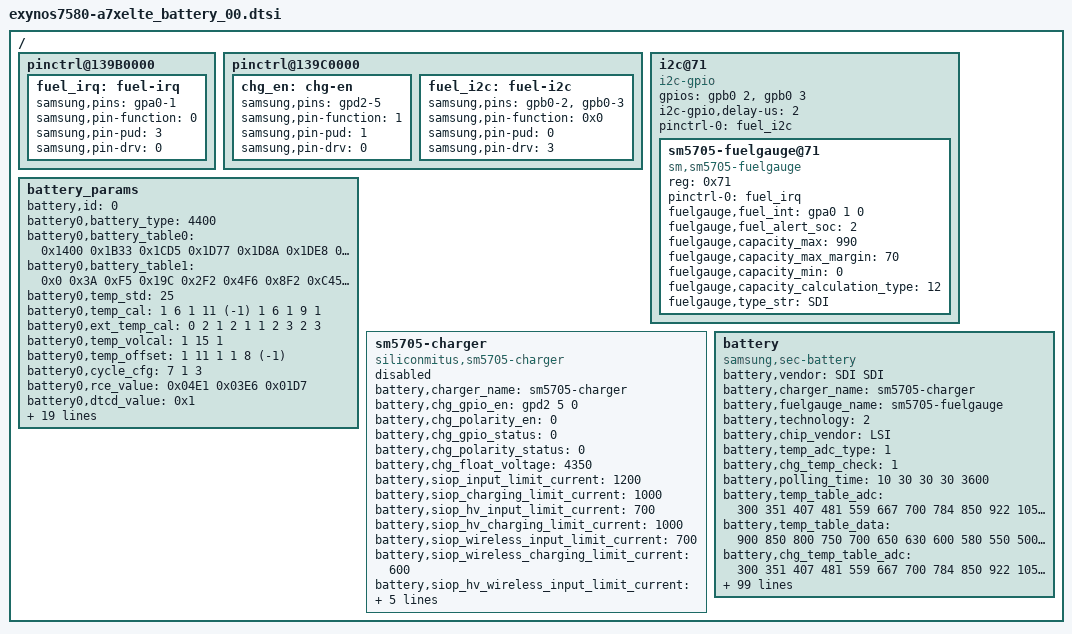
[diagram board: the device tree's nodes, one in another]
/*
 * SAMSUNG UNIVERSAL5430 board device tree source
 *
 * Copyright (c) 2013 Samsung Electronics Co., Ltd.
 *		http://www.samsung.com
 *
 * This program is free software; you can redistribute it and/or modify
 * it under the terms of the GNU General Public License version 2 as
 * published by the Free Software Foundation.
*/

/ {
	pinctrl@139B0000 {
		fuel_irq: fuel-irq {
			samsung,pins = "gpa0-1";
			samsung,pin-function = <0>;
			samsung,pin-pud = <3>;
			samsung,pin-drv = <0>;
		};
	};

	pinctrl@139C0000 {
		chg_en: chg-en {
			samsung,pins = "gpd2-5";
			samsung,pin-function = <1>;
			samsung,pin-pud = <1>;
			samsung,pin-drv = <0>;
		};

		fuel_i2c: fuel-i2c {
			samsung,pins = "gpb0-2", "gpb0-3";
			samsung,pin-function = <0x0>;
			samsung,pin-pud = <0>;
			samsung,pin-drv = <3>;
		};
	};

	i2c@71 {
		compatible = "i2c-gpio";
		gpios = <&gpb0 2 0x0 /*sda*/
			&gpb0 3 0x0  /*scl*/
			>;
		i2c-gpio,delay-us = <2>;
		#address-cells = <1>;
		#size-cells = <0>;
		pinctrl-names = "default";
		pinctrl-0 = <&fuel_i2c>;
		status = "okay";

		sm5705-fuelgauge@71 {
			compatible = "sm,sm5705-fuelgauge";
			reg = <0x71>;
			pinctrl-names = "default";
			pinctrl-0 = <&fuel_irq>;
			fuelgauge,fuel_int = <&gpa0 1 0>;
			fuelgauge,fuel_alert_soc = <2>;
			fuelgauge,capacity_max = <990>;
			fuelgauge,capacity_max_margin = <70>;
			fuelgauge,capacity_min = <0>;
			fuelgauge,capacity_calculation_type = <12>;
			fuelgauge,type_str = "SDI";
		};
	};

	battery_params {
		battery,id = <0>; /* -1 means auto, detected by F/G */
		battery0,battery_type = <4400>; /* 4200 4350 4400 */
		battery0,battery_table0 = <0x1400 0x1B33 0x1CD5 0x1D77 0x1D8A 0x1DE8 0x1E50 0x1EA7 0x1EFE 0x1F9D 0x1FF3 0x2090 0x20AA 0x2147 0x2266 0x2400>;
		battery0,battery_table1 = <0x0 0x3A 0xF5 0x19C 0x2F2 0x4F6 0x8F2 0xC45 0xE49 0x1047 0x1245 0x139B 0x1442 0x1646 0x1933 0x1939>;
		battery0,temp_std = <25>;
		battery0,temp_cal = <1 6 1 11 (-1) 1 6 1 9 1>; /* en_h, p_de, p_fa, n_de, n_fa, en_l, p_de, p_fa, n_de, n_fa, */
		battery0,ext_temp_cal = <0 2 1 2 1 1 2 3 2 3>; /* en_h, p_de, p_fa, n_de, n_fa, en_l, p_de, p_fa, n_de, n_fa, */
		battery0,temp_volcal = <1 15 1>; /* en, temp, cal */
		battery0,temp_offset = <1 11 1 1 8 (-1)>; /* en_high level offset en_low level offset */
		battery0,cycle_cfg = <7 1 3>; /*high_limit low_limit cntl*/
		battery0,rce_value = <0x04E1 0x03E6 0x01D7>;
		battery0,dtcd_value = <0x1>;
		battery0,rs_value = <0x0051 0x147 0x47a 0x3800 0x00a4>; /*rs p_mix_factor n_mix_factor max min*/
		battery0,vit_period = <0x3506>;
		battery0,mix_value = <0x0503 0x0004>; /*mix_rate init_blank*/
		battery0,misc = <0x0060>;
		battery0,topoff_soc = <0 3 300>; /*enable soc current*/
		battery0,curr_offset = <1 0x0000>; /*en_auto offset*/
		battery0,volt_cal = <0x8000>;
		battery0,p_curr_cal = <0x009C>;
		battery0,n_curr_cal = <0x009C>;
		battery0,curr_lcal = <0 0x8888 0x8888 0x8888>;
		battery0,tem_poff = <3350 50 3200 50>;
		battery0,v_offset_cancel = <1 0 100 10>; /* en_p, en_n, level, mohm */
		battery0,v_alarm = <3000>;
		battery0,v_max_table = <0x2266 0x223C 0x2212 0x21E8 0x217F>;
		battery0,q_max_table = <0x1933 0x18CB 0x1863 0x17FC 0x16F8>;
		battery0,data_ver = <0x8>; /* this is must set value same with .version in BL */
	};

	sm5705-charger {
		status = "disable";
		compatible = "siliconmitus,sm5705-charger";

		/* Charger */
		battery,charger_name = "sm5705-charger";
		battery,chg_gpio_en = <&gpd2 5 0>;
		battery,chg_polarity_en = <0>;
		battery,chg_gpio_status = <0>;
		battery,chg_polarity_status = <0>;
		battery,chg_float_voltage = <4350>;

		battery,siop_input_limit_current = <1200>;
		battery,siop_charging_limit_current = <1000>;
		battery,siop_hv_input_limit_current = <700>;
		battery,siop_hv_charging_limit_current = <1000>;

		battery,siop_wireless_input_limit_current = <700>;
		battery,siop_wireless_charging_limit_current = <600>;
		battery,siop_hv_wireless_input_limit_current = <500>;
		battery,siop_hv_wireless_charging_limit_current = <1000>;
		battery,siop_call_cv_current = <500>;
		battery,siop_call_cc_current = <500>;
	};

	battery {
		status = "okay";

		compatible = "samsung,sec-battery";
		battery,vendor = "SDI SDI";
		battery,charger_name = "sm5705-charger";
		battery,fuelgauge_name = "sm5705-fuelgauge";
		battery,technology = <2>; /* POWER_SUPPLY_TECHNOLOGY_LION */
		/* .temp_cohot = -1000; */
		/* .temp_cocold = -4325; */

		battery,chip_vendor = "LSI";
		battery,temp_adc_type = <1>; /* SEC_BATTERY_ADC_TYPE_AP */

		battery,chg_temp_check = <1>;

		battery,polling_time = <10 30 30 30 3600>;

		battery,temp_table_adc = <300 351 407 481 559 667 700 784 850 922 1056 1189 1404 1602 2026 2245 2460 2874 2932 3180 3229 3305 3335 3410>;
		battery,temp_table_data = <900 850 800 750 700 650 630 600 580 550 500 460 400 350 250 200 150 50 0 (-50) (-70) (-100) (-150) (-200)>;

		battery,chg_temp_table_adc = <300 351 407 481 559 667 700 784 850 922 1056 1189 1404 1602 2026 2245 2460 2874 2932 3180 3229 3305 3335 3410>;
		battery,chg_temp_table_data = <900 850 800 750 700 650 630 600 580 550 500 460 400 350 250 200 150 50 0 (-50) (-70) (-100) (-150) (-200)>;

		battery,input_current_limit = <1800 0 0 1800 460 900 1000 460 1000 0 820 1900 1800 0 0 400 700 1300 300 1000 1500 0 1650 500 1650 80 1800 1650 1400 1000 1000 1800>;
		battery,fast_charging_current = <2100 0 0 2100 460 1200 1000 460 1200 0 1200 1600 2100 0 0 400 700 1300 300 1000 1500 0 2350 1000 2350 80 1800 1000 1400 0 1000 2100>;
		battery,full_check_current_1st = <325 0 0 325 325 325 325 325 325 0 325 325 325 0 0 325 325 325 325 325 325 0 325 325 325 0 325 325 325 0 325 325>; /* 0.1C */
		battery,full_check_current_2nd = <175 0 0 175 175 175 175 175 175 0 175 175 175 0 0 175 175 175 175 175 175 0 175 175 175 0 175 175 175 0 175 175>; /*0.05C */

		battery,inbat_voltage = <1>;
		battery,inbat_voltage_table_adc = <2739 2722 2697 2678 2643 2628 2599 2573 2547 2521 2495 2474 2440 2423 2393 2359 2347 2317 2291 2267 2240>;
		battery,inbat_voltage_table_data = <438 435 430 426 419 416 410 405 400 395 390 385 380 375 370 365 360 355 350 345 340>;

		battery,adc_check_count = <5>;

		battery,cable_check_type = <4>; /* SEC_BATTERY_CABLE_CHECK_PSY */
		battery,cable_source_type = <1>; /* SEC_BATTERY_CABLE_SOURCE_EXTERNAL */
		battery,event_waiting_time = <600>;
		battery,polling_type = <1>; /* SEC_BATTERY_MONITOR_ALARM */
		battery,monitor_initial_count = <0>;

		battery,battery_check_type = <0>; /* SEC_BATTERY_CHECK_NONE */
		battery,check_count = <0>;
		battery,check_adc_max = <1440>;
		battery,check_adc_min = <0>;

		battery,ovp_uvlo_check_type = <3>; /* SEC_BATTERY_OVP_UVLO_CHGPOLLING */

		battery,thermal_source = <2>; /* SEC_BATTERY_THERMAL_SOURCE_ADC */

		battery,temp_check_type = <2>; /* SEC_BATTERY_TEMP_CHECK_TEMP */
		battery,temp_check_count = <1>;
		battery,temp_highlimit_threshold_event = <800>;
		battery,temp_highlimit_recovery_event = <750>;
		battery,temp_high_threshold_event = <500>;
		battery,temp_high_recovery_event = <450>;
		battery,temp_low_threshold_event = <0>;
		battery,temp_low_recovery_event = <50>;
		battery,temp_highlimit_threshold_normal = <800>;
		battery,temp_highlimit_recovery_normal = <750>;
		battery,temp_high_threshold_normal = <500>;
		battery,temp_high_recovery_normal = <450>;
		battery,temp_low_threshold_normal = <0>;
		battery,temp_low_recovery_normal = <50>;
		battery,temp_highlimit_threshold_lpm = <800>;
		battery,temp_highlimit_recovery_lpm = <750>;
		battery,temp_high_threshold_lpm = <500>;
		battery,temp_high_recovery_lpm = <450>;
		battery,temp_low_threshold_lpm = <0>;
		battery,temp_low_recovery_lpm = <50>;
		battery,full_check_type = <2>; /* SEC_BATTERY_FULLCHARGED_FG_CURRENT */
		battery,full_check_type_2nd = <2>; /* SEC_BATTERY_FULLCHARGED_FG_CURRENT */
		battery,full_check_count = <3>;
		battery,chg_gpio_full_check = <0>;
		battery,chg_polarity_full_check = <1>;

		battery,chg_high_temp_1st = <465>;
		battery,chg_high_temp_2nd = <465>;
		battery,chg_high_temp_recovery = <455>;
		battery,chg_charging_limit_current = <1400>;
		battery,chg_charging_limit_current_2nd = <1400>;
		battery,chg_skip_check_capacity = <10>;
		battery,chg_skip_check_time = <600>;

		/* SEC_BATTERY_FULL_CONDITION_SOC |
		   SEC_BATTERY_FULL_CONDITION_NOTIMEFULL |
		   SEC_BATTERY_FULL_CONDITION_VCELL */
		battery,full_condition_type = <13>;
		battery,full_condition_soc = <93>;
		battery,full_condition_vcell = <4250>;

		battery,recharge_check_count = <2>;
		battery,recharge_condition_type = <4>; /* SEC_BATTERY_RECHARGE_CONDITION_VCELL */
		battery,recharge_condition_soc = <98>;
		battery,recharge_condition_vcell = <4280>;

		battery,standard_curr = <2350>;
		battery,expired_time = <12000>;
		battery,recharging_expired_time = <5400>;
		battery,charging_reset_time = <0>;

		battery,chg_float_voltage = <4350>;

		/*battery,self_discharging_en;*/
		battery,self_discharging_type = <2>;	/* SELF_DISCHARGING_BY_CHG */
		battery,force_discharging_limit = <650>;
		battery,force_discharging_recov = <550>;
		battery,self_discharging_voltage_limit = <4250>;

		battery,self_discharging_temp_block = <600>;
		battery,self_discharging_volt_block = <4250>;
		battery,self_discharging_temp_recov = <550>;
		battery,self_discharging_temp_pollingtime = <400>;

		/* swelling setting */
		battery,swelling_low_temp_2step_mode = <1>;
		battery,swelling_high_temp_block = <410>;
		battery,swelling_high_temp_recov = <390>;
		battery,swelling_low_temp_block_1st = <150>;
		battery,swelling_low_temp_recov_1st = <200>;
		battery,swelling_low_temp_block_2nd = <50>;
		battery,swelling_low_temp_recov_2nd = <100>;

		battery,swelling_low_temp_current = <950>;		/* 0.3C */
		battery,swelling_low_temp_topoff = <175>;		/* 0.05C */
		battery,swelling_high_temp_current = <1450>;	/* 0.45C */
		battery,swelling_high_temp_topoff = <175>;		/* 0.05C */

		battery,swelling_drop_float_voltage = <4150>;
		battery,swelling_high_rechg_voltage = <4000>;
		battery,swelling_low_rechg_voltage = <4000>;
		battery,swelling_block_time = <600>;

		/* cycle, chg_float_voltage, recharge_condition_vcell, full_condition_vcell, full_condition_soc */
		battery,age_data = <0 4350 4280 4250 93
				200 4330 4260 4230 92
				250 4310 4240 4210 91
				300 4290 4220 4190 90
				1000 4240 4170 4140 89>;

		io-channels = <&exynos_adc 1>, <&exynos_adc 3>, <&exynos_adc 4>;
		io-channel-names = "adc-temp", "chg-adc-temp", "in-bat-adc";
		#io-channel-cells = <3>;
		io-channel-ranges;
	};
};
